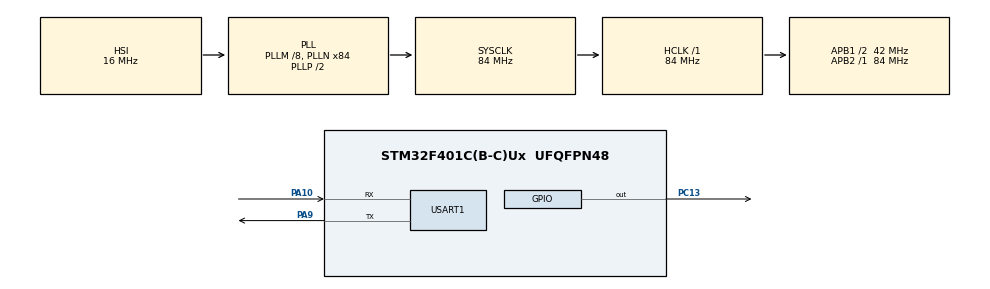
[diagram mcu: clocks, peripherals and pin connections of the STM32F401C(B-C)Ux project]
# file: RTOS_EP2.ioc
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FREERTOS.Queues01=Norm_Q,16,uint16_t,0,Dynamic,NULL,NULL
FREERTOS.Tasks01=Task1,24,128,Task1_Handler,Default,NULL,Dynamic,NULL,NULL;Task2,24,128,Task2_Handler,Default,NULL,Dynamic,NULL,NULL
FREERTOS.configENABLE_FPU=1
FREERTOS.configUSE_NEWLIB_REENTRANT=1
Mcu.Family=STM32F4
Mcu.Name=STM32F401C(B-C)Ux
Mcu.Package=UFQFPN48
NVIC.PriorityGroup=NVIC_PRIORITYGROUP_4
NVIC.TIM1_BRK_TIM9_IRQn=true\:15\:0\:false\:false\:true\:false\:false\:true\:true
NVIC.TimeBase=TIM1_BRK_TIM9_IRQn
NVIC.TimeBaseIP=TIM9
NVIC.USART1_IRQn=true\:5\:0\:false\:false\:true\:true\:true\:true\:true
PA10.Mode=Asynchronous
PA10.Signal=USART1_RX
PA13.Mode=JTAG_4_pins
PA13.Signal=SYS_JTMS-SWDIO
PA14.Mode=JTAG_4_pins
PA14.Signal=SYS_JTCK-SWCLK
PA15.Mode=JTAG_4_pins
PA15.Signal=SYS_JTDI
PA9.Mode=Asynchronous
PA9.Signal=USART1_TX
PB3.Mode=JTAG_4_pins
PB3.Signal=SYS_JTDO-SWO
PC13-ANTI_TAMP.Signal=GPIO_Output
PH0\ -\ OSC_IN.Mode=HSE-External-Oscillator
PH0\ -\ OSC_IN.Signal=RCC_OSC_IN
PH1\ -\ OSC_OUT.Mode=HSE-External-Oscillator
PH1\ -\ OSC_OUT.Signal=RCC_OSC_OUT
ProjectManager.HeapSize=0x200
ProjectManager.StackSize=0x400
ProjectManager.TargetToolchain=STM32CubeIDE
RCC.48MHZClocksFreq_Value=42000000
RCC.AHBFreq_Value=84000000
RCC.APB1CLKDivider=RCC_HCLK_DIV2
RCC.APB1Freq_Value=42000000
RCC.APB1TimFreq_Value=84000000
RCC.APB2Freq_Value=84000000
RCC.APB2TimFreq_Value=84000000
RCC.CortexFreq_Value=84000000
RCC.HCLKFreq_Value=84000000
RCC.HSE_VALUE=25000000
RCC.HSI_VALUE=16000000
RCC.LSE_VALUE=32768
RCC.PLLM=8
RCC.PLLN=84
RCC.SYSCLKFreq_VALUE=84000000
RCC.SYSCLKSource=RCC_SYSCLKSOURCE_PLLCLK
RCC.VCOOutputFreq_Value=168000000
USART1.VirtualMode=VM_ASYNC
VP_FREERTOS_VS_CMSIS_V2.Mode=CMSIS_V2
VP_SYS_VS_tim9.Mode=TIM9
board=custom

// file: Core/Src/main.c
/* USER CODE BEGIN Header */
/**
  ******************************************************************************
  * @file           : main.c
  * @brief          : Main program body
  ******************************************************************************
  * @attention
  *
  * Copyright (c) 2024 STMicroelectronics.
  * All rights reserved.
  *
  * This software is licensed under terms that can be found in the LICENSE file
  * in the root directory of this software component.
  * If no LICENSE file comes with this software, it is provided AS-IS.
  *
  ******************************************************************************
  */
/* USER CODE END Header */
#include "main.h"
#include "cmsis_os.h"

/* USER CODE BEGIN Includes */
#include <stdio.h>
#include <string.h>
/* USER CODE END Includes */

/* USER CODE BEGIN PD */
#define BUFFER_SIZE 50
/* USER CODE END PD */

UART_HandleTypeDef huart1;

/* Definitions for Task1 */
osThreadId_t Task1Handle;
const osThreadAttr_t Task1_attributes = {
  .name = "Task1",
  .stack_size = 128 * 4,
  .priority = (osPriority_t) osPriorityNormal,
};
/* Definitions for Task2 */
osThreadId_t Task2Handle;
const osThreadAttr_t Task2_attributes = {
  .name = "Task2",
  .stack_size = 128 * 4,
  .priority = (osPriority_t) osPriorityNormal,
};
/* Definitions for Norm_Q */
osMessageQueueId_t Norm_QHandle;
const osMessageQueueAttr_t Norm_Q_attributes = {
  .name = "Norm_Q"
};
/* USER CODE BEGIN PV */

char *Task1_str = "Hello, it's task1\r\n";
char *Task2_str = "Hello, it's task2\r\n";

uint8_t rxData;
uint8_t u8_rxbuff[BUFFER_SIZE];
uint8_t buffer_idx = 0;

uint8_t sig = 10;

/* USER CODE END PV */

void SystemClock_Config(void);
static void MX_GPIO_Init(void);
static void MX_USART1_UART_Init(void);
void Task1_Handler(void *argument);
void Task2_Handler(void *argument);

int main(void)
{

  /* MCU Configuration--------------------------------------------------------*/

  /* Reset of all peripherals, Initializes the Flash interface and the Systick. */
  HAL_Init();

  /* Configure the system clock */
  SystemClock_Config();

  /* Initialize all configured peripherals */
  MX_GPIO_Init();
  MX_USART1_UART_Init();
  /* USER CODE BEGIN 2 */
  HAL_UART_Receive_IT(&huart1, &rxData, 1);
  /* USER CODE END 2 */

  /* Init scheduler */
  osKernelInitialize();

  /* Create the queue(s) */
  /* creation of Norm_Q */
  Norm_QHandle = osMessageQueueNew (16, sizeof(uint16_t), &Norm_Q_attributes);

  /* Create the thread(s) */
  /* creation of Task1 */
  Task1Handle = osThreadNew(Task1_Handler, NULL, &Task1_attributes);

  /* creation of Task2 */
  Task2Handle = osThreadNew(Task2_Handler, NULL, &Task2_attributes);

  /* Start scheduler */
  osKernelStart();
  /* We should never get here as control is now taken by the scheduler */
  /* Infinite loop */
  while (1)
  {

  }
}

void SystemClock_Config(void)
{
  RCC_OscInitTypeDef RCC_OscInitStruct = {0};
  RCC_ClkInitTypeDef RCC_ClkInitStruct = {0};

  /** Configure the main internal regulator output voltage
  */
  __HAL_RCC_PWR_CLK_ENABLE();
  __HAL_PWR_VOLTAGESCALING_CONFIG(PWR_REGULATOR_VOLTAGE_SCALE2);

  /** Initializes the RCC Oscillators according to the specified parameters
  * in the RCC_OscInitTypeDef structure.
  */
  RCC_OscInitStruct.OscillatorType = RCC_OSCILLATORTYPE_HSI;
  RCC_OscInitStruct.HSIState = RCC_HSI_ON;
  RCC_OscInitStruct.HSICalibrationValue = RCC_HSICALIBRATION_DEFAULT;
  RCC_OscInitStruct.PLL.PLLState = RCC_PLL_ON;
  RCC_OscInitStruct.PLL.PLLSource = RCC_PLLSOURCE_HSI;
  RCC_OscInitStruct.PLL.PLLM = 8;
  RCC_OscInitStruct.PLL.PLLN = 84;
  RCC_OscInitStruct.PLL.PLLP = RCC_PLLP_DIV2;
  RCC_OscInitStruct.PLL.PLLQ = 4;
  if (HAL_RCC_OscConfig(&RCC_OscInitStruct) != HAL_OK)
  {
    Error_Handler();
  }

  /** Initializes the CPU, AHB and APB buses clocks
  */
  RCC_ClkInitStruct.ClockType = RCC_CLOCKTYPE_HCLK|RCC_CLOCKTYPE_SYSCLK
                              |RCC_CLOCKTYPE_PCLK1|RCC_CLOCKTYPE_PCLK2;
  RCC_ClkInitStruct.SYSCLKSource = RCC_SYSCLKSOURCE_PLLCLK;
  RCC_ClkInitStruct.AHBCLKDivider = RCC_SYSCLK_DIV1;
  RCC_ClkInitStruct.APB1CLKDivider = RCC_HCLK_DIV2;
  RCC_ClkInitStruct.APB2CLKDivider = RCC_HCLK_DIV1;

  if (HAL_RCC_ClockConfig(&RCC_ClkInitStruct, FLASH_LATENCY_2) != HAL_OK)
  {
    Error_Handler();
  }
}

static void MX_USART1_UART_Init(void)
{

  huart1.Instance = USART1;
  huart1.Init.BaudRate = 115200;
  huart1.Init.WordLength = UART_WORDLENGTH_8B;
  huart1.Init.StopBits = UART_STOPBITS_1;
  huart1.Init.Parity = UART_PARITY_NONE;
  huart1.Init.Mode = UART_MODE_TX_RX;
  huart1.Init.HwFlowCtl = UART_HWCONTROL_NONE;
  huart1.Init.OverSampling = UART_OVERSAMPLING_16;
  if (HAL_UART_Init(&huart1) != HAL_OK)
  {
    Error_Handler();
  }

}

static void MX_GPIO_Init(void)
{
  GPIO_InitTypeDef GPIO_InitStruct = {0};

  /* GPIO Ports Clock Enable */
  __HAL_RCC_GPIOC_CLK_ENABLE();
  __HAL_RCC_GPIOH_CLK_ENABLE();
  __HAL_RCC_GPIOA_CLK_ENABLE();
  __HAL_RCC_GPIOB_CLK_ENABLE();

  /*Configure GPIO pin Output Level */
  HAL_GPIO_WritePin(GPIOC, GPIO_PIN_13, GPIO_PIN_RESET);

  /*Configure GPIO pin : PC13 */
  GPIO_InitStruct.Pin = GPIO_PIN_13;
  GPIO_InitStruct.Mode = GPIO_MODE_OUTPUT_PP;
  GPIO_InitStruct.Pull = GPIO_NOPULL;
  GPIO_InitStruct.Speed = GPIO_SPEED_FREQ_LOW;
  HAL_GPIO_Init(GPIOC, &GPIO_InitStruct);

}

/* USER CODE BEGIN 4 */
void HAL_UART_RxCpltCallback(UART_HandleTypeDef *huart)
{
	if(huart->Instance == USART1)
	{
		if(rxData != 13)
		{
			u8_rxbuff[buffer_idx++] = rxData;
			if(buffer_idx > BUFFER_SIZE)
				buffer_idx = 0;
		}
		else if(rxData == 13)
		{
			u8_rxbuff[buffer_idx] = '\0';

			HAL_UART_Transmit(&huart1, (uint8_t *)u8_rxbuff, buffer_idx, 50);
			buffer_idx = 0;
		}
		HAL_UART_Receive_IT(&huart1, &rxData, 1);
	}

}
/* USER CODE END 4 */

void Task1_Handler(void *argument)
{
  /* USER CODE BEGIN 5 */
	HAL_UART_Transmit(&huart1, (uint8_t *)Task1_str, strlen(Task1_str), 20);

	osMessageQueuePut(Norm_QHandle, &sig, 1, portMAX_DELAY);
	osMessageQueueGetMsgSize(Norm_QHandle);

	/* Infinite loop */
  for(;;)
  {
   	HAL_GPIO_TogglePin(GPIOC, GPIO_PIN_13);
   	osDelay(1000);
  }
  /* USER CODE END 5 */
}

void Task2_Handler(void *argument)
{
  /* USER CODE BEGIN Task2_Handler */
	//HAL_UART_Transmit(&huart1, (uint8_t *)Task2_str, strlen(Task2_str), 20);
  /* Infinite loop */
  for(;;)
  {
    osDelay(1000);
  }
  /* USER CODE END Task2_Handler */
}

void HAL_TIM_PeriodElapsedCallback(TIM_HandleTypeDef *htim)
{
  if (htim->Instance == TIM9) {
    HAL_IncTick();
  }
}

void Error_Handler(void)
{
  __disable_irq();
  while (1)
  {
  }
}
